# PIC32MX174F256D device description
Architecture: MIPS; Family: PIC32MX; Series: PIC32MX
Registers are 32-bit, read-write, no defined reset value unless marked. A register's access mark holds for its fields unless they carry their own. Offsets are from the block's base; [hi:lo] are bit positions; {n}, {i} and the like mark numbered series.

## PMP
Instances: PMP 0x1f807000 in periph0
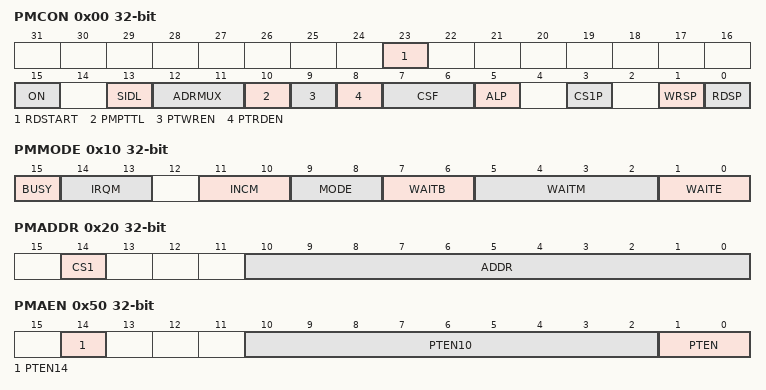
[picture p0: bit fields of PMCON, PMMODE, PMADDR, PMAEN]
0x00 PMCON — Parallel Port Control Register
  [23] RDSTART — Start Read on PMP Bus bit
    1=Start a read cycle on the PMP bus; 0=No effect
  [15] ON — Parallel Master Port Enable bit
    1=PMP is enabled; 0=PMP disabled, no off-chip access performed
  [13] SIDL — Stop in Idle Mode bit
    1=Discontinue module operation when device enters Idle mode; 0=Continue module operation when the device enters Idle mode
  [12:11] ADRMUX — Address/Data Multiplexing Selection bits
    3=Lower 8 bits of address are multiplexed on PMD pins; upper 8 bits are not used; 2=All 16 bits of address are multiplexed on PMD pins; 1=Lower 8 bits of address are multiplexed on PMD pins, upper bits are on PMA(10-8) and PMCS1; 0=Address and data appear on separate pins
  [10] PMPTTL — PMP Module TTL Input Buffer Select bit
    1=PMP module uses TTL input buffers; 0=PMP module uses Schmitt Trigger input buffer
  [9] PTWREN — Write Enable Strobe Port Enable bit
    1=PMWR/PMENB port is enabled; 0=PMWR/PMENB port is disabled
  [8] PTRDEN — Read/Write Strobe Port Enable bit
    1=PMRD/PMWR port is enabled; 0=PMRD/PMWR port is disabled
  [7:6] CSF — Chip Select Function bits
    2=PMCS1 and PMCS2 function as Chip Select
  [5] ALP — Address Latch Polarity bit
    1=Active-high (PMALL and PMALH); 0=Active-low (PMALL and PMALH)
  [3] CS1P — Chip Select 1 Polarity bit
    1=Active-high (PMCS1); 0=Active-low (PMCS1)
  [1] WRSP — Write Strobe Polarity bit
    1=(Slave and Master mode 2) Write strobe active-high / (Master mode 1) Enable strobe active-high; 0=(Slave and Master mode 2) Write strobe active-low / (Master mode 1) Enable strobe active-low
  [0] RDSP — Read Strobe Polarity bit
    1=(Slave and Master mode 2) Read Strobe active-high / (master mode 1) Read/write strobe active-high; 0=(Slave and Master mode 2) Read Strobe active-low / (Master mode 1) Read/write strobe active-low
0x10 PMMODE — Parallel Port Mode Register
  [15] BUSY — Busy bit
    1=Port is busy; 0=Port is not busy
  [14:13] IRQM — Interrupt Request Mode bits
    2=Interrupt is generated when Read Buffer 3 is read or Write Buffer 3 is written (Buffered PSP mode)or on a read or write operation when PMA = 11 (Addressable Slave mode only); 1=Interrupt is generated at the end of the read/write cycle; 0=No Interrupt is generated
  [11:10] INCM — Increment Mode bits
    3=Slave mode read and write buffers auto-increment (MODE = 00 only); 2=Decrement ADDR(10:2) and ADDR(14) by 1 every read/write cycle; 1=Increment ADDR(10:2) and ADDR(14) by 1 every read/write cycle; 0=No increment or decrement of address
  [9:8] MODE — Parallel Port Mode Select bits
    3=Master mode 1 (PMCS1, PMRD/PMWR, PMENB, PMA, and PMD); 2=Master mode 2 (PMCS1, PMRD, PMWR, PMA, and PMD); 1=Enhanced Slave mode, control signals (PMRD, PMWR, PMCS1, PMD, and PMA; 0=Legacy Parallel Slave Port, control signals (PMRD, PMWR, PMCS1, and PMD
  [7:6] WAITB — Data Setup to Read/Write Strobe Wait States bits
    {v}=Data wait of {v+1} Tpbclk2 (v=0..3)
  [5:2] WAITM — Data Read/Write Strobe Wait States bits
    {v}=Wait of {v+1} Tpbclk2 (v=1..15); 0=Wait of 1 Tpbclk2 (default)
  [1:0] WAITE — Data Hold After Read/Write Strobe Wait States bits
    3=(for writes) Wait of 4 Tpbclk2 / (for reads) Wait of 3 Tpbclk2; 2=(for writes) Wait of 3 Tpbclk2 / (for reads) Wait of 2 Tpbclk2; 1=(for writes) Wait of 2 Tpbclk2 / (for reads) Wait of 1 Tpbclk2; 0=(for writes) Wait of 1 Tpbclk2 (default) / (for reads) Wait of 0 Tpbclk2 (default)
0x20 PMADDR — Parallel Port Address Register
  [14] CS1 — Chip Select 1 bit
    1=Chip Select 1 is active; 0=Chip Select 1 is inactive
  [10:0] ADDR — Destination Address bits
    0=Address is 0
0x30 PMDOUT — Parallel Port Output Data Register
  [31:0] DATAOUT
0x40 PMDIN — Parallel Port Input Data Register
  [31:0] DATAIN
0x50 PMAEN — Parallel Port Pin Enable Register
  [14] PTEN14 — PMCS1 Address Port Enable bit
    1=PMCS1; 0=PMCS1 functions as port I/O
  [10:2] PTEN10 — PMP Address Port Enable bits
    0x7fc=PMA(10:2) function as PMP address lines; 0=PMA(10:2) function as port I/O
  [1:0] PTEN — PMALH/PMALL Port Enable bits
    1=PMA1 and PMA0 function as either PMA or PMALH and PMALL; 0=PMA1 and PMA0 pads function as port I/O
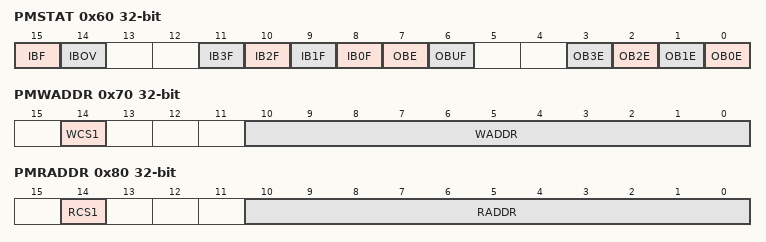
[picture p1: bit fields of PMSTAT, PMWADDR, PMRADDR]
0x60 PMSTAT — Parallel Port Status Register (Slave modes only)
  [15] IBF — Input Buffer Full Status bit
    1=All writable input buffer registers are full; 0=Some or all of the writable input buffer registers are empty
  [14] IBOV — Input Buffer Overflow Status bit
    1=A write attempt to a full input byte buffer is occurred (must be cleared in software); 0=No overflow is occurred
  [n+8] IB{n}F (n=0..3) — Input Buffer {n} Status Full bit
    1=Input Buffer contains data that has not been read (reading buffer will clear this bit); 0=Input Buffer does not contain any unread data
  [7] OBE — Output Buffer Empty Status bit
    1=All readable output buffer registers are empty; 0=Some or all of the readable output buffer registers are full
  [6] OBUF — Output Buffer Underflow Status bit
    1=A read occurred from an empty output byte buffer (must be cleared in software); 0=No underflow is occurred
  [n] OB{n}E (n=0..3) — Output Buffer {n} Status Empty bit
    1=Output buffer is empty (writing data to the buffer will clear this bit); 0=Output buffer contains data that has not been transmitted
0x70 PMWADDR — Parallel Port Write Address Register
  [14] WCS1 — Chip Select 1 bit
    1=Chip Select 1 is active; 0=Chip Select 1 is inactive, PMA14 is active
  [10:0] WADDR — Address bits
    0=Address is 0
0x80 PMRADDR — Parallel Port Read Address Register
  [14] RCS1 — Chip Select 1 bit
    1=Chip Select 1 is active; 0=Chip Select 1 is inactive (RADDR14 function is selected)
  [10:0] RADDR — Address bits
0x90 PMRDIN — Parallel Port Read Input Data Register
  [15:0] RDATAIN
Value list PMRDIN__RDATAIN: 0=Port Read Input Data Bits are 0

## Notices in the file
Copyright (c) 2019 Microchip Technology Inc.
SPDX-License-Identifier: Apache-2.0
Licensed under the Apache License, Version 2.0 (the "License");
you may not use this file except in compliance with the License.
You may obtain a copy of the License at
http://www.apache.org/licenses/LICENSE-2.0
Unless required by applicable law or agreed to in writing, software
distributed under the License is distributed on an "AS IS" BASIS,
WITHOUT WARRANTIES OR CONDITIONS OF ANY KIND, either express or implied.
See the License for the specific language governing permissions and
limitations under the License.
